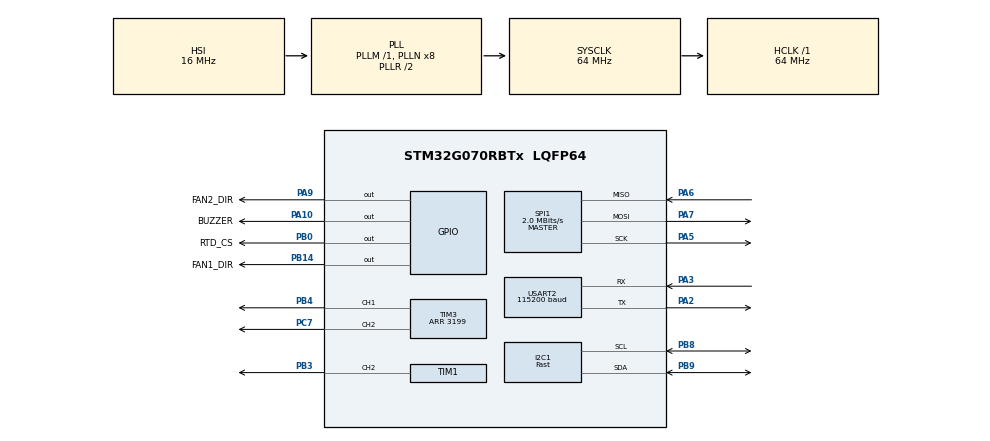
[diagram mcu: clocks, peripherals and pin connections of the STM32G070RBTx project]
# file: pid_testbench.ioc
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I2C1.I2C_Speed_Mode=I2C_Fast
I2C1.Timing=0x00602173
IWDG.Prescaler=IWDG_PRESCALER_32
IWDG.Reload=2000
Mcu.Family=STM32G0
Mcu.Name=STM32G070RBTx
Mcu.Package=LQFP64
NVIC.TIM6_IRQn=true\:2\:0\:false\:false\:true\:true\:true\:true
NVIC.USART2_IRQn=true\:1\:0\:false\:false\:true\:true\:true\:true
PA10.GPIO_Label=BUZZER
PA10.Signal=GPIO_Output
PA13.Mode=Serial_Wire
PA13.Signal=SYS_SWDIO
PA14-BOOT0.Mode=Serial_Wire
PA14-BOOT0.Signal=SYS_SWCLK
PA2.GPIO_PuPd=GPIO_PULLUP
PA2.Mode=Asynchronous
PA2.Signal=USART2_TX
PA3.GPIO_PuPd=GPIO_PULLUP
PA3.Mode=Asynchronous
PA3.Signal=USART2_RX
PA5.GPIO_Speed=GPIO_SPEED_FREQ_HIGH
PA5.Mode=Full_Duplex_Master
PA5.Signal=SPI1_SCK
PA6.GPIO_Speed=GPIO_SPEED_FREQ_HIGH
PA6.Mode=Full_Duplex_Master
PA6.Signal=SPI1_MISO
PA7.GPIO_Speed=GPIO_SPEED_FREQ_HIGH
PA7.Mode=Full_Duplex_Master
PA7.Signal=SPI1_MOSI
PA9.GPIO_Label=FAN2_DIR
PA9.Signal=GPIO_Output
PB0.GPIO_Label=RTD_CS
PB0.GPIO_Speed=GPIO_SPEED_FREQ_HIGH
PB0.PinState=GPIO_PIN_SET
PB0.Signal=GPIO_Output
PB14.GPIO_Label=FAN1_DIR
PB14.Signal=GPIO_Output
PB3.GPIO_PuPd=GPIO_PULLUP
PB3.Signal=S_TIM1_CH2
PB4.GPIO_PuPd=GPIO_PULLDOWN
PB4.Signal=S_TIM3_CH1
PB8.GPIO_PuPd=GPIO_PULLUP
PB8.Mode=I2C
PB8.Signal=I2C1_SCL
PB9.GPIO_PuPd=GPIO_PULLUP
PB9.Mode=I2C
PB9.Signal=I2C1_SDA
PC7.GPIO_PuPd=GPIO_PULLDOWN
PC7.Signal=S_TIM3_CH2
ProjectManager.HeapSize=0x400
ProjectManager.StackSize=0x800
ProjectManager.TargetToolchain=STM32CubeIDE
RCC.AHBFreq_Value=64000000
RCC.CortexFreq_Value=64000000
RCC.EXTERNAL_CLOCK_VALUE=48000
RCC.HCLKFreq_Value=64000000
RCC.HSE_VALUE=8000000
RCC.HSI_VALUE=16000000
RCC.PLLN=8
RCC.SYSCLKFreq_VALUE=64000000
RCC.SYSCLKSource=RCC_SYSCLKSOURCE_PLLCLK
RCC.VCOOutputFreq_Value=128000000
SH.S_TIM1_CH2.0=TIM1_CH2,PWM Generation2 CH2
SH.S_TIM3_CH1.0=TIM3_CH1,PWM Generation1 CH1
SH.S_TIM3_CH2.0=TIM3_CH2,PWM Generation2 CH2
SPI1.BaudRatePrescaler=SPI_BAUDRATEPRESCALER_32
SPI1.CLKPhase=SPI_PHASE_2EDGE
SPI1.CalculateBaudRate=2.0 MBits/s
SPI1.DataSize=SPI_DATASIZE_8BIT
SPI1.Direction=SPI_DIRECTION_2LINES
SPI1.Mode=SPI_MODE_MASTER
SPI1.VirtualType=VM_MASTER
TIM1.AutoReloadPreload=TIM_AUTORELOAD_PRELOAD_ENABLE
TIM1.Channel-PWM\ Generation2\ CH2=TIM_CHANNEL_2
TIM1.OCIdleState_2=TIM_OCIDLESTATE_SET
TIM1.OCPolarity_2=TIM_OCPOLARITY_LOW
TIM1.OffStateIDLEMode=TIM_OSSI_ENABLE
TIM1.OffStateRunMode=TIM_OSSR_ENABLE
TIM1.Period=3199
TIM3.AutoReloadPreload=TIM_AUTORELOAD_PRELOAD_ENABLE
TIM3.Channel-PWM\ Generation1\ CH1=TIM_CHANNEL_1
TIM3.Channel-PWM\ Generation2\ CH2=TIM_CHANNEL_2
TIM3.Period=3199
TIM6.Period=999
TIM6.Prescaler=63
USART2.BaudRate=115200
USART2.VirtualMode-Asynchronous=VM_ASYNC
VP_IWDG_VS_IWDG.Mode=IWDG_Activate
VP_TIM1_VS_ClockSourceINT.Mode=Internal
VP_TIM3_VS_ClockSourceINT.Mode=Internal
VP_TIM6_VS_ClockSourceINT.Mode=Enable_Timer
board=custom

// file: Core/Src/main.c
/* USER CODE BEGIN Header */
/*
 * PID temperature testbench, NUCLEO-G070RB.
 *
 * Peripheral setup comes from pid_testbench.ioc (STM32CubeMX). All of the
 * testbench itself lives in app.c and the modules it pulls in; this file
 * only brings the chip up and hands over.
 */
/* USER CODE END Header */

#include "main.h"
#include "i2c.h"
#include "iwdg.h"
#include "spi.h"
#include "tim.h"
#include "usart.h"
#include "gpio.h"

/* USER CODE BEGIN Includes */
#include "app.h"
/* USER CODE END Includes */

void SystemClock_Config(void);

int main(void)
{
  HAL_Init();
  SystemClock_Config();

  MX_GPIO_Init();
  MX_TIM1_Init();
  MX_TIM3_Init();
  MX_TIM6_Init();
  MX_SPI1_Init();
  MX_I2C1_Init();
  MX_USART2_UART_Init();
  MX_IWDG_Init();

  /* USER CODE BEGIN 2 */
  app_init();
  /* USER CODE END 2 */

  while (1)
  {
    /* USER CODE BEGIN 3 */
    app_loop();
    /* USER CODE END 3 */
  }
}

/* HSI16 -> PLL -> 64 MHz SYSCLK, APB at 64 MHz. */
void SystemClock_Config(void)
{
  RCC_OscInitTypeDef RCC_OscInitStruct = {0};
  RCC_ClkInitTypeDef RCC_ClkInitStruct = {0};

  HAL_PWREx_ControlVoltageScaling(PWR_REGULATOR_VOLTAGE_SCALE1);

  RCC_OscInitStruct.OscillatorType = RCC_OSCILLATORTYPE_HSI;
  RCC_OscInitStruct.HSIState = RCC_HSI_ON;
  RCC_OscInitStruct.HSIDiv = RCC_HSI_DIV1;
  RCC_OscInitStruct.HSICalibrationValue = RCC_HSICALIBRATION_DEFAULT;
  RCC_OscInitStruct.PLL.PLLState = RCC_PLL_ON;
  RCC_OscInitStruct.PLL.PLLSource = RCC_PLLSOURCE_HSI;
  RCC_OscInitStruct.PLL.PLLM = RCC_PLLM_DIV1;
  RCC_OscInitStruct.PLL.PLLN = 8;
  RCC_OscInitStruct.PLL.PLLP = RCC_PLLP_DIV2;
  RCC_OscInitStruct.PLL.PLLR = RCC_PLLR_DIV2;
  if (HAL_RCC_OscConfig(&RCC_OscInitStruct) != HAL_OK)
  {
    Error_Handler();
  }

  RCC_ClkInitStruct.ClockType = RCC_CLOCKTYPE_HCLK | RCC_CLOCKTYPE_SYSCLK | RCC_CLOCKTYPE_PCLK1;
  RCC_ClkInitStruct.SYSCLKSource = RCC_SYSCLKSOURCE_PLLCLK;
  RCC_ClkInitStruct.AHBCLKDivider = RCC_SYSCLK_DIV1;
  RCC_ClkInitStruct.APB1CLKDivider = RCC_HCLK_DIV1;
  if (HAL_RCC_ClockConfig(&RCC_ClkInitStruct, FLASH_LATENCY_2) != HAL_OK)
  {
    Error_Handler();
  }
}

void Error_Handler(void)
{
  /* USER CODE BEGIN Error_Handler_Debug */
  /* Something failed during start-up. Force the SSR line high (heater off),
   * then hang; the watchdog resets the chip if it's already running. */
  __disable_irq();
  GPIO_InitTypeDef gpio = {0};
  __HAL_RCC_GPIOB_CLK_ENABLE();
  gpio.Pin = GPIO_PIN_3;
  gpio.Mode = GPIO_MODE_OUTPUT_PP;
  HAL_GPIO_WritePin(GPIOB, GPIO_PIN_3, GPIO_PIN_SET);
  HAL_GPIO_Init(GPIOB, &gpio);
  while (1)
  {
  }
  /* USER CODE END Error_Handler_Debug */
}
